# STM32G553xx register map
File version: 1.0
Registers are 32-bit, read-write, reset 0x0 unless marked. A register's access mark holds for its fields unless they carry their own. Offsets are from the block's base; [hi:lo] are bit positions; {n}, {i} and the like mark numbered series.

## ICACHE — Instruction cache (ICACHE)
Base 0x40030400
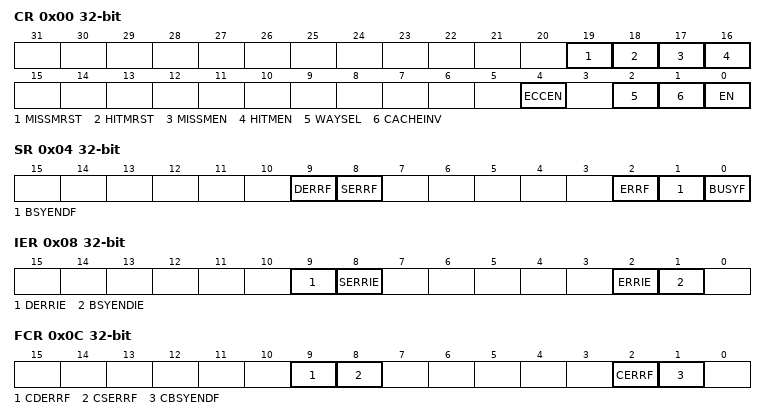
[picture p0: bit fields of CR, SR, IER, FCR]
0x00 CR — ICACHE control register
  [19] MISSMRST — miss monitor reset
  [18] HITMRST — hit monitor reset
  [17] MISSMEN — miss monitor enable
  [16] HITMEN — hit monitor enable
  [4] ECCEN — ECC enable
  [2] WAYSEL — cache associativity mode selection
  [1] CACHEINV — cache invalidation
  [0] EN — enable
0x04 SR — ICACHE status register
  [9] DERRF — ECC double-bit error flag
  [8] SERRF — ECC single-bit error flag
  [2] ERRF — cache error flag
  [1] BSYENDF — busy end flag
  [0] BUSYF — busy flag
0x08 IER — ICACHE interrupt enable register
  [9] DERRIE
  [8] SERRIE
  [2] ERRIE — interrupt enable on cache error
  [1] BSYENDIE — interrupt enable on busy end
0x0C FCR — ICACHE flag clear register
  [9] CDERRF — clear ECC double-bit error flag
  [8] CSERRF — clear ECC single-bit error flag
  [2] CERRF — clear cache error flag
  [1] CBSYENDF — clear busy end flag
0x10 HMONR ro — ICACHE hit monitor register
  [31:0] HITMON — cache hit monitor counter
0x14 MMONR ro — ICACHE miss monitor register
  [15:0] MISSMON — cache miss monitor counter
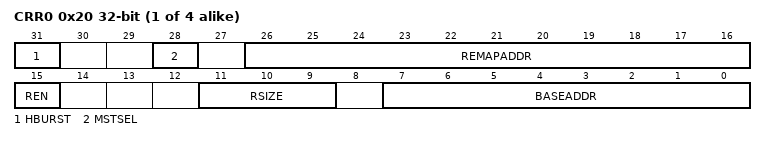
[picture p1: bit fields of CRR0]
{0x20+4i} CRR{i} (i=0..3) — ICACHE region {i} configuration register
  [31] HBURST — output burst type for region x
  [28] MSTSEL — AHB cache master selection for region x
  [26:16] REMAPADDR — remapped address for region x
  [15] REN — enable for region x
  [11:9] RSIZE — size for region x
  [7:0] BASEADDR — base address for region x

## DCACHE — Data cache (DCACHE)
Base 0x40031400
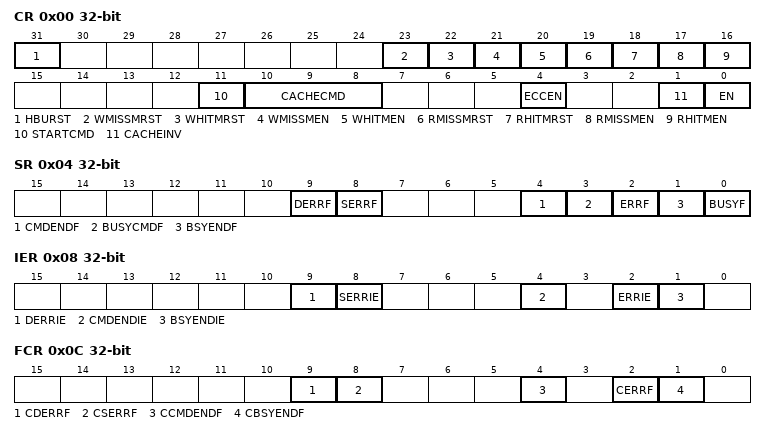
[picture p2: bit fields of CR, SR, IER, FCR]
0x00 CR — DCACHE control register
  [31] HBURST
  [23] WMISSMRST
  [22] WHITMRST
  [21] WMISSMEN
  [20] WHITMEN
  [19] RMISSMRST
  [18] RHITMRST
  [17] RMISSMEN
  [16] RHITMEN
  [11] STARTCMD
  [10:8] CACHECMD
  [4] ECCEN — ECC enable
  [1] CACHEINV
  [0] EN — enable
0x04 SR — DCACHE status register
  [9] DERRF
  [8] SERRF
  [4] CMDENDF — command end flag
  [3] BUSYCMDF — command busy flag
  [2] ERRF — cache error flag
  [1] BSYENDF
  [0] BUSYF
0x08 IER — DCACHE interrupt enable register
  [9] DERRIE, [8] SERRIE, [4] CMDENDIE, [2] ERRIE, [1] BSYENDIE
0x0C FCR — DCACHE flag clear register
  [9] CDERRF, [8] CSERRF, [4] CCMDENDF, [2] CERRF, [1] CBSYENDF
0x10 RHMONR ro — DCACHE read-hit monitor register
  [31:0] RHITMON
0x14 RMMONR ro — DCACHE read-miss monitor register
  [15:0] RMISSMON
0x20 WHMONR ro — DCACHE write-hit monitor register
  [31:0] WHITMON
0x24 WMMONR ro — DCACHE write-miss monitor register
  [15:0] WMISSMON
0x28 CMDRSADDRR — DCACHE command range start address register
  [31:4] CMDSTARTADDR
0x2C CMDREADDRR — DCACHE command range end address register
  [31:4] CMDENDADDR

## GTZC1_TZSC1_PERIPH
Base 0x40032400
0x00 CR — TZSC control register
  [0] LCK
{0x10+4i} SECCFGR{i} (i=0..2) — TZSC secure configuration register
{0x20+4i} PRIVCFGR{i} (i=0..2) — TZSC privilege configuration register

## GTZC1_TZIC1
Base 0x40032800
{0x0+4i} IER{i} (i=0..3) — TZIC interrupt enable register
{0x10+4i} SR{i} (i=0..3) — TZIC status register
{0x20+4i} FCR{i} (i=0..3) — TZIC flag clear register

## GTZC1_MPCBB1
Base 0x40032C00
Same registers: GTZC1_MPCBB2 0x40033000, GTZC1_MPCBB3 0x40033400
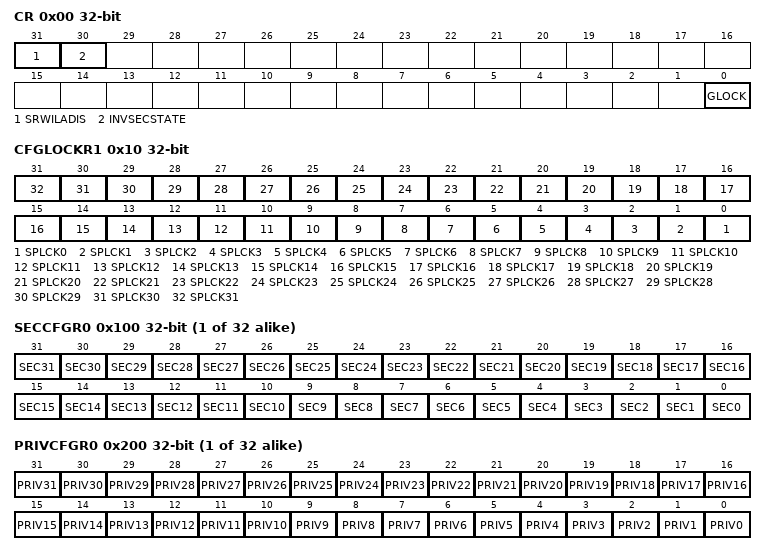
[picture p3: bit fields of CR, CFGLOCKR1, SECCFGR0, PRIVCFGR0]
0x00 CR — MPCBBx control register
  [31] SRWILADIS, [30] INVSECSTATE, [0] GLOCK
0x10 CFGLOCKR1 — MPCBBx lock register
  [n] SPLCK{n} (n=0..31)
{0x100+4i} SECCFGR{i} (i=0..31) — MPCBBx security configuration registers
  [n] SEC{n} (n=0..31)
{0x200+4i} PRIVCFGR{i} (i=0..31) — MPCBBx privilege configuration registers
  [n] PRIV{n} (n=0..31)

## ADC12_COMMON
Base 0x42020300
0x00 CSR ro — ADC common status register
0x08 CCR — ADC common control register
0x0C CDR ro — ADC common regular data register for dual mode
0x10 CDR2 ro — ADC common regular data register for dual mode
